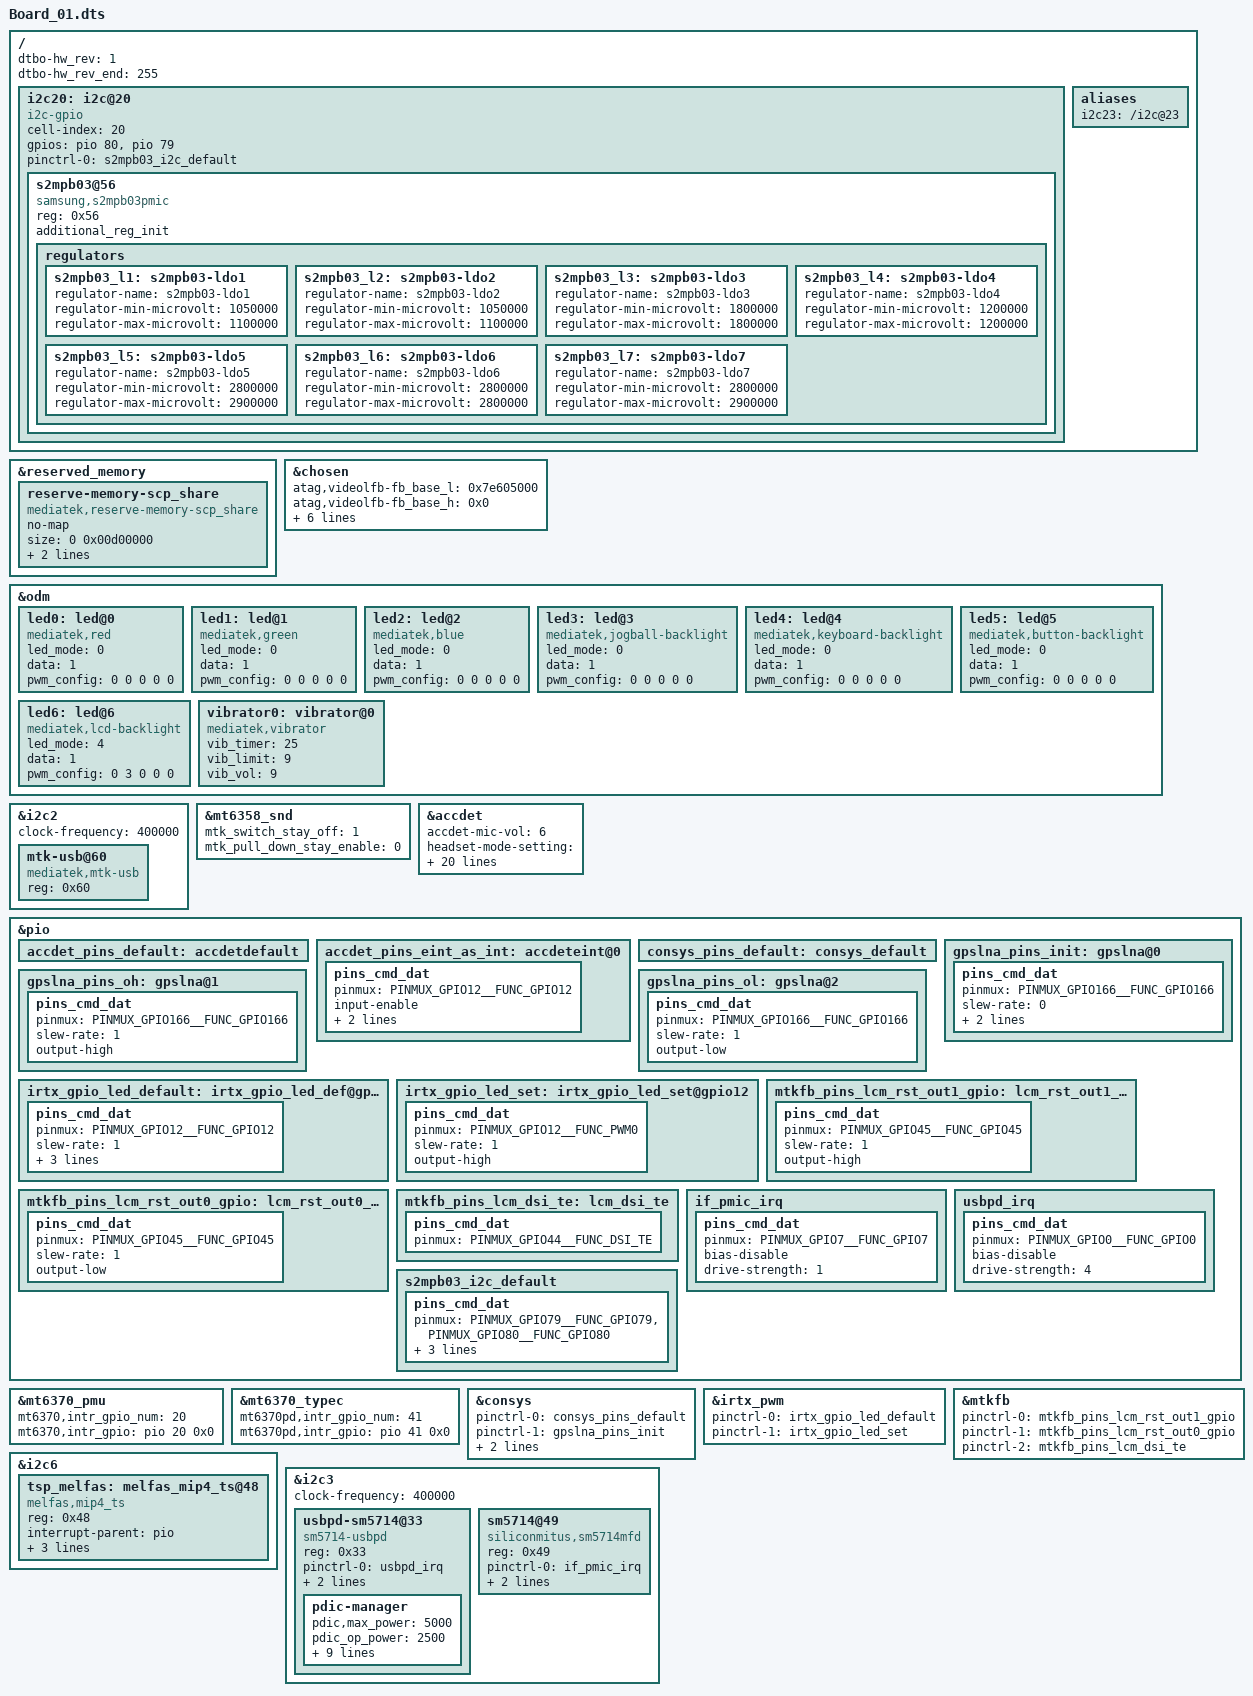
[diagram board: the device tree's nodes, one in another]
/*
 * Copyright (C) 2019 MediaTek Inc.
 *
 * This program is free software; you can redistribute it and/or modify
 * it under the terms of the GNU General Public License version 2 as
 * published by the Free Software Foundation.
 *
 * This program is distributed in the hope that it will be useful,
 * but WITHOUT ANY WARRANTY; without even the implied warranty of
 * MERCHANTABILITY or FITNESS FOR A PARTICULAR PURPOSE.
 * See http://www.gnu.org/licenses/gpl-2.0.html for more details.
 */

/dts-v1/;
/plugin/;
#include <dt-bindings/interrupt-controller/irq.h>
#include <dt-bindings/interrupt-controller/arm-gic.h>
#include <dt-bindings/pinctrl/mt6768-pinfunc.h>

/ {
	fragment@model {
	target-path = "/";
		__overlay__ {
			dtbo-hw_rev = <1>;
			dtbo-hw_rev_end = <255>;
		};
	};
};

&reserved_memory {
	reserve-memory-scp_share {
		compatible = "mediatek,reserve-memory-scp_share";
		no-map;
		size = <0 0x00d00000>;
		alignment = <0 0x1000000>;
		alloc-ranges = <0 0x40000000 0 0x50000000>;
	};
};

/* chosen */
&chosen {

	atag,videolfb-fb_base_l = <0x7e605000>;
	atag,videolfb-fb_base_h = <0x0>;
	atag,videolfb-islcmfound = <1>;
	atag,videolfb-islcm_inited = <0>;
	atag,videolfb-fps= <6000>;
	atag,videolfb-vramSize= <0x017e8000>;
	atag,videolfb-lcmname=
		"hx83112b_fhdp_dsi_cmd_auo_rt5081_drv";
};

&odm {
	led0:led@0 {
		compatible = "mediatek,red";
		led_mode = <0>;
		data = <1>;
		pwm_config = <0 0 0 0 0>;
	};
	led1:led@1 {
		compatible = "mediatek,green";
		led_mode = <0>;
		data = <1>;
		pwm_config = <0 0 0 0 0>;
	};
	led2:led@2 {
		compatible = "mediatek,blue";
		led_mode = <0>;
		data = <1>;
		pwm_config = <0 0 0 0 0>;
	};
	led3:led@3 {
		compatible = "mediatek,jogball-backlight";
		led_mode = <0>;
		data = <1>;
		pwm_config = <0 0 0 0 0>;
	};
	led4:led@4 {
		compatible = "mediatek,keyboard-backlight";
		led_mode = <0>;
		data = <1>;
		pwm_config = <0 0 0 0 0>;
	};
	led5:led@5 {
		compatible = "mediatek,button-backlight";
		led_mode = <0>;
		data = <1>;
		pwm_config = <0 0 0 0 0>;
	};
	led6:led@6 {
		compatible = "mediatek,lcd-backlight";
		led_mode = <4>;
		data = <1>;
		pwm_config = <0 3 0 0 0>;
	};
	vibrator0:vibrator@0 {
		compatible = "mediatek,vibrator";
		vib_timer = <25>;
		vib_limit = <9>;
		vib_vol= <9>;
	};
};

&i2c2 {
	clock-frequency = <400000>;

	mtk-usb@60 {
		compatible = "mediatek,mtk-usb";
		reg = <0x60>;
		status = "okay";
	};
};

/* mt6358 pmic customize setting */
&mt6358_snd {
	mtk_switch_stay_off = <1>;
	mtk_pull_down_stay_enable = <0>;
};

/* accdet start */
&accdet {
	/* accdet micbias voltage: 0x07,2.7v;0x05,2.5v;0x02,1.9v */
	accdet-mic-vol = <6>;
	headset-mode-setting = <0x500 0x500 1 0x1f0 0x800 0x800 0x20 0x44>;
	accdet-plugout-debounce = <1>;
	/*1:ACC mode, 2:low cost without in bias, 6:low cost with in bias*/
	accdet-mic-mode = <1>;
	/* eint_level_trigger: 8,LEVEL_LOW(DEF) ;4,LV_HIGH;others,LV_LOW */
	headset-eint-level-pol = <8>;
	/*min_3pole--max_3pole--min_4pole--max_4pole--vol_bias*/
	headset-vol-threshold = <0 590 591 2000 2600>;
	/*0--MD_MAX--UP_MAX--DW_MAX*/
	headset-three-key-threshold = <0 80 220 400>;
	headset-three-key-threshold-CDD = <0 121 192 600>;
	/*0--MD_MAX--VOICE_MAX--UP_MAX--DW_MAX*/
	headset-four-key-threshold = <0 83 115 189 400>;

	/* moisture SW mode config start, use external resister or not.
	 */
	moisture-ver = <1>;
	moisture-plug-in-threshold = <0 514 749>;
	moisture_use_ext_res = <1>;
	/* moisture of water resister ohm, SW mode by auxadc*/
	moisture-water-r = <50000>;
	moisture-vm = <100>;
	/* moisture SW mode config end */

	/* ACCDET GPIO standardization for AP EINT */
	pinctrl-names = "default", "state_eint_as_int";
	pinctrl-0 = <&accdet_pins_default>;
	pinctrl-1 = <&accdet_pins_eint_as_int>;
	interrupt-parent = <&pio>;
	interrupts = <12 IRQ_TYPE_LEVEL_LOW 12 0x0>;
	deb-gpios = <&pio 12 0>;
	plugin-debounce = <512000>;
	plugout-debounce = <500>;
	status = "okay";
};
&pio {
	accdet_pins_default: accdetdefault {
	};
	accdet_pins_eint_as_int: accdeteint@0 {
		pins_cmd_dat {
			pinmux = <PINMUX_GPIO12__FUNC_GPIO12>;
			input-enable;
			slew-rate = <0>;
			bias-disable;
		};
	};
};
/* accdet end */

&mt6370_pmu {
	mt6370,intr_gpio_num = <20>; /* direct defined GPIO num */
	mt6370,intr_gpio = <&pio 20 0x0>;
};
&mt6370_typec {
	mt6370pd,intr_gpio_num = <41>; /* direct defined GPIO num */
	mt6370pd,intr_gpio = <&pio 41 0x0>;
};

/* CONSYS GPIO standardization */
&pio {
	consys_pins_default: consys_default {
	};
	gpslna_pins_init: gpslna@0 {
		pins_cmd_dat {
			pinmux = <PINMUX_GPIO166__FUNC_GPIO166>;
			slew-rate = <0>;
			bias-disable;
			output-low;
		};
	};
	gpslna_pins_oh: gpslna@1 {
		pins_cmd_dat {
			pinmux = <PINMUX_GPIO166__FUNC_GPIO166>;
			slew-rate = <1>;
			output-high;
		};
	};
	gpslna_pins_ol: gpslna@2 {
		pins_cmd_dat {
			pinmux = <PINMUX_GPIO166__FUNC_GPIO166>;
			slew-rate = <1>;
			output-low;
		};
	};
};
&consys {
	pinctrl-names = "default", "gps_lna_state_init",
		"gps_lna_state_oh", "gps_lna_state_ol";
	pinctrl-0 = <&consys_pins_default>;
	pinctrl-1 = <&gpslna_pins_init>;
	pinctrl-2 = <&gpslna_pins_oh>;
	pinctrl-3 = <&gpslna_pins_ol>;
	status = "okay";
};
/* CONSYS end */

/* IRTX GPIO Start */
&irtx_pwm {
	pinctrl-names = "irtx_gpio_led_default", "irtx_gpio_led_set";
	pinctrl-0 = <&irtx_gpio_led_default>;
	pinctrl-1 = <&irtx_gpio_led_set>;
	status = "okay";
};
&pio {
	/* IRTX GPIO Settings -Start */
	/* default: GPIO0, output, high */
	irtx_gpio_led_default:irtx_gpio_led_def@gpio12 {
		pins_cmd_dat {
			pinmux = <PINMUX_GPIO12__FUNC_GPIO12>;
			slew-rate = <1>;
			bias-disable;
			output-low;
			input-schmitt-enable = <0>;
		};
	};

	irtx_gpio_led_set:irtx_gpio_led_set@gpio12 {
		pins_cmd_dat {
			pinmux = <PINMUX_GPIO12__FUNC_PWM0>;
			slew-rate = <1>;
			output-high;
		};
	};
}; /* IRTX GPIO Settings -End */

/* DISPSYS GPIO standardization */
&pio {
	mtkfb_pins_lcm_rst_out1_gpio: lcm_rst_out1_gpio {
		pins_cmd_dat {
			pinmux = <PINMUX_GPIO45__FUNC_GPIO45>;
			slew-rate = <1>;
			output-high;
		};
	};

	mtkfb_pins_lcm_rst_out0_gpio: lcm_rst_out0_gpio {
		pins_cmd_dat {
			pinmux = <PINMUX_GPIO45__FUNC_GPIO45>;
			slew-rate = <1>;
			output-low;
		};
	};

	mtkfb_pins_lcm_dsi_te: lcm_dsi_te {
		pins_cmd_dat {
			pinmux = <PINMUX_GPIO44__FUNC_DSI_TE>;
		};
	};
};

&mtkfb {
	pinctrl-names =
		"lcm_rst_out1_gpio", "lcm_rst_out0_gpio",
		"mode_te_te";
	pinctrl-0 = <&mtkfb_pins_lcm_rst_out1_gpio>;
	pinctrl-1 = <&mtkfb_pins_lcm_rst_out0_gpio>;
	pinctrl-2 = <&mtkfb_pins_lcm_dsi_te>;
	status = "okay";
};

/* DISPSYS GPIO standardization end*/

/* TSP Start */
&i2c6 {
	tsp_melfas:melfas_mip4_ts@48 {
		compatible = "melfas,mip4_ts";
		reg = <0x48>;
		interrupt-parent = <&pio>;
		interrupts = <10 0x0>;
		tsp_avdd-supply = <&mt_pmic_vcama2_ldo_reg>;
		pinctrl-names = "enable", "disable";
		irq-gpio = <&pio 10 0x0>;
	};
};
/* TSP End */

#include "mediatek/k69v1_64_titan_buffalo/gpio01.dtsi"
#include "mediatek/k69v1_64_titan_buffalo/cust_mt6768_camera01.dtsi"

&pio {
	if_pmic_irq: if_pmic_irq {
		pins_cmd_dat {
			pinmux = <PINMUX_GPIO7__FUNC_GPIO7>;
			bias-disable;
			drive-strength = /bits/ 8 <1>;
		};
	};
	usbpd_irq: usbpd_irq {
		pins_cmd_dat {
			pinmux = <PINMUX_GPIO0__FUNC_GPIO0>;
			bias-disable;
			drive-strength = /bits/ 8 <4>;
		};
	};
};

&i2c3 {
	#address-cells = <1>;
	#size-cells = <0>;
	status = "okay";
	clock-frequency = <400000>;

	usbpd-sm5714@33 {
		status = "okay";
		compatible = "sm5714-usbpd";
		reg = <0x33>;
		pinctrl-names = "default";
		pinctrl-0 = <&usbpd_irq>;
		usbpd,usbpd_int = <&pio 0 0>;

		support_pd_role_swap;
		pdic-manager {
			/* sink */
			pdic,max_power = <5000>;
			pdic_op_power = <2500>;
			pdic_max_voltage = <6000>;
			pdic_max_current = <2000>;
			pdic,min_current = <500>;
			pdic,giveback = <0>;
			pdic,usb_com_capable = <1>;
			pdic,no_usb_suspend = <1>;

			/* source */
			source,max_voltage = <5000>;
			source,min_voltage = <4000>;
			source,max_power = <2500>;
		};
	};

	sm5714@49{
		status = "okay";
		compatible = "siliconmitus,sm5714mfd";
		reg = <0x49>;
		pinctrl-names = "default";
		pinctrl-0 = <&if_pmic_irq>;
		sm5714,irq-gpio = <&pio 7 0>;
		sm5714,wakeup;
	};
};

&pio {
	s2mpb03_i2c_default: s2mpb03_i2c_default {
		pins_cmd_dat {
			pinmux = <PINMUX_GPIO79__FUNC_GPIO79>, <PINMUX_GPIO80__FUNC_GPIO80>;
			input-enable;
			slew-rate = <0>;
			bias-disable;
		};
	};
};

/ {
	fragment@model {
		target-path = "/";
		__overlay__ {
			/* S2MPB03 Camera PMIC */
			i2c20: i2c@20 {
				status = "okay";
				cell-index = <20>;
				compatible = "i2c-gpio";
				gpios = <&pio 80 0 /* sda */
						&pio 79 0 /* scl */>;
				pinctrl-names = "default";
				pinctrl-0 = <&s2mpb03_i2c_default>;

				s2mpb03@56 {
					compatible = "samsung,s2mpb03pmic";
					reg = <0x56>;
					additional_reg_init;
					regulators {
						s2mpb03_l1: s2mpb03-ldo1 {	/* RCAM1_DVDD_1P1 */
							regulator-name = "s2mpb03-ldo1";
							regulator-min-microvolt = <1050000>;
							regulator-max-microvolt = <1100000>;
						};
						s2mpb03_l2: s2mpb03-ldo2 {	/* FCAM_DVDD_1P05 */
							regulator-name = "s2mpb03-ldo2";
							regulator-min-microvolt = <1050000>;
							regulator-max-microvolt = <1100000>;
						};
						s2mpb03_l3: s2mpb03-ldo3 {	/* CAM_DVDDIO_1P8 */
							regulator-name = "s2mpb03-ldo3";
							regulator-min-microvolt = <1800000>;
							regulator-max-microvolt = <1800000>;
						};
						s2mpb03_l4: s2mpb03-ldo4 {	/* RCAM3_DVDD_1P2 */
							regulator-name = "s2mpb03-ldo4";
							regulator-min-microvolt = <1200000>;
							regulator-max-microvolt = <1200000>;
						};
						s2mpb03_l5: s2mpb03-ldo5 {	/*RCAM1_AVDD1_2P9*/
							regulator-name = "s2mpb03-ldo5";
							regulator-min-microvolt = <2800000>;
							regulator-max-microvolt = <2900000>;
						};
						s2mpb03_l6: s2mpb03-ldo6 {	/* RCAM2_AVDD_2P8 */
							regulator-name = "s2mpb03-ldo6";
							regulator-min-microvolt = <2800000>;
							regulator-max-microvolt = <2800000>;
						};
						s2mpb03_l7: s2mpb03-ldo7 {	/* FCAM_AVDD_2P9 */
							regulator-name = "s2mpb03-ldo7";
							regulator-min-microvolt = <2800000>;
							regulator-max-microvolt = <2900000>;
						};
					};
				};
			};

			aliases {
				i2c23 = "/i2c@23";
			};
		};
	};
};

#include "mediatek/ssdev_in_mtk/sm5714_fuelgauge.a32_lte.dtsi"
#include "mediatek/ssdev_in_mtk/battery_common.a32_lte.dtsi"
/*End of this file, DO NOT ADD ANYTHING HERE*/
